# BCM2711_PCIE register map
File version: 1
BCM2711 PCIe bridge
Registers are read-write, no defined reset value unless marked. A register's access mark holds for its fields unless they carry their own. Offsets are from the block's base; lines under a group give offsets from that group; [hi:lo] are bit positions; {n}, {i} and the like mark numbered series; 'fields as' and 'values as' point back to an identical list; <NAME> marks a mode.

## Memory map
0x00000000 BCM2711_PCIE size 0x9310

## BCM2711_PCIE
Base 0x00000000
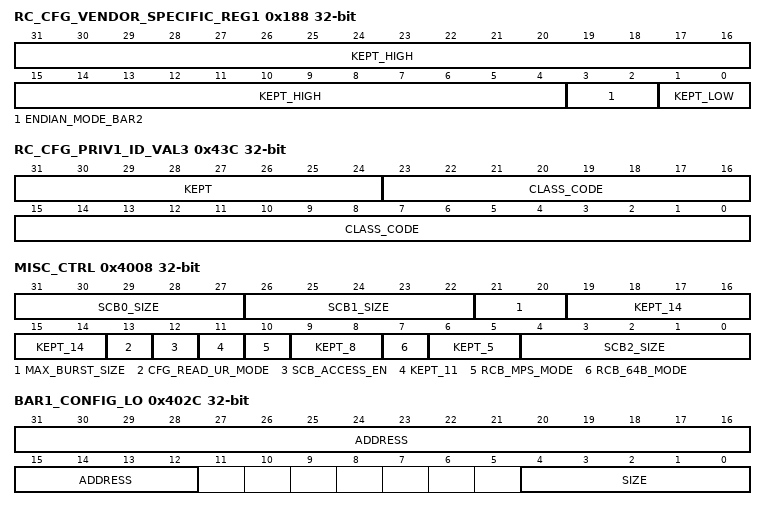
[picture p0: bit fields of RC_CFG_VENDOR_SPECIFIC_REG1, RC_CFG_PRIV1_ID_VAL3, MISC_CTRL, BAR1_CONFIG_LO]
0x188 RC_CFG_VENDOR_SPECIFIC_REG1 — The root port's vendor register 1: the inbound window's byte order
  [31:4] KEPT_HIGH — Bits no source names, kept as read
  [3:2] ENDIAN_MODE_BAR2 — Byte order of inbound window BAR2
    0=LITTLE
  [1:0] KEPT_LOW — Bits no source names, kept as read
0x43C RC_CFG_PRIV1_ID_VAL3 — The root port's class code, which resets as an endpoint's
  [31:24] KEPT — Bits no source names, kept as read
  [23:0] CLASS_CODE — Base class, subclass and programming interface
    0x60400=PCI_TO_PCI_BRIDGE
0x4008 MISC_CTRL — MISC_MISC_CTRL: bus access, burst and the memory controllers' sizes
  [31:27] SCB0_SIZE — Memory controller 0's size, as its base-2 logarithm less 15
  [26:22] SCB1_SIZE — Memory controller 1's size; unused on the BCM2711
  [21:20] MAX_BURST_SIZE — The longest burst on the system bus
    0=BYTES_128; 1=BYTES_256; 2=BYTES_512
  [19:14] KEPT_14 — Bits no source names, kept as read
  [13] CFG_READ_UR_MODE — A configuration read completing with Unsupported Request returns data (inference)
  [12] SCB_ACCESS_EN — Lets the bridge reach the system bus
  [11] KEPT_11 — A bit no source names, kept as read
  [10] RCB_MPS_MODE — Read completion boundary from the payload size; no source says what it changes
  [9:8] KEPT_8 — Bits no source names, kept as read
  [7] RCB_64B_MODE — Read completion boundary of 64 bytes; no source says what it changes
  [6:5] KEPT_5 — Bits no source names, kept as read
  [4:0] SCB2_SIZE — Memory controller 2's size; unused on the BCM2711
{0x400C+8i} WIN_LO[{i}] (i=0..3) — CPU_2_PCIE_MEM_WIN_LO: outbound window w's PCI address, low word
  [31:0] ADDRESS — The PCI address's bits 31:0
{0x4010+8i} WIN_HI[{i}] (i=0..3) — CPU_2_PCIE_MEM_WIN_HI: outbound window w's PCI address, high word
  [31:0] ADDRESS — The PCI address's bits 63:32
0x402C BAR1_CONFIG_LO — MISC_RC_BAR1_CONFIG_LO: inbound window 1, which on this family maps the SoC's registers; kept disabled
  [31:12] ADDRESS — The PCI address's bits 31:12
  [4:0] SIZE — The window's size code; 0 disables it
    0=DISABLED
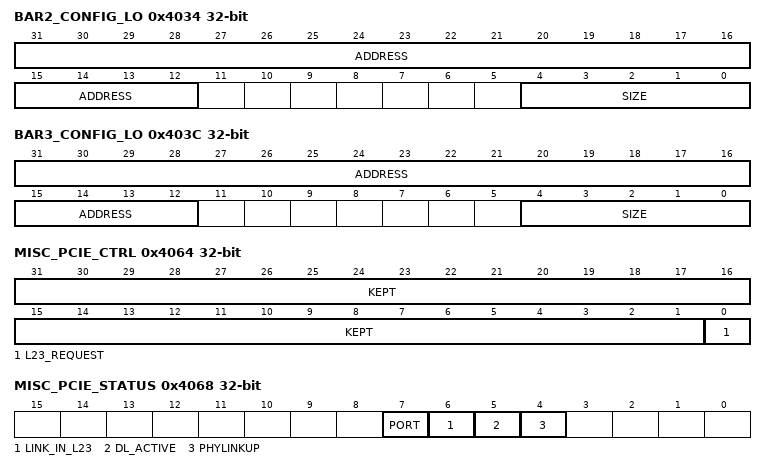
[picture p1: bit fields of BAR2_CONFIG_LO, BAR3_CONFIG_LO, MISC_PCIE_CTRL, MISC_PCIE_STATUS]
0x4034 BAR2_CONFIG_LO — MISC_RC_BAR2_CONFIG_LO: inbound window 2, the one that maps memory from CPU address 0
  [31:12] ADDRESS — The PCI address's bits 31:12
  [4:0] SIZE — The window's size code: log2(size) - 15 from 64 KiB to 64 GiB, log2(size) - 12 + 0x1c from 4 KiB to 32 KiB; 0 disables it
    0=DISABLED
0x4038 BAR2_CONFIG_HI — MISC_RC_BAR2_CONFIG_HI: inbound window 2's PCI address, high word
  [31:0] ADDRESS — The PCI address's bits 63:32
0x403C BAR3_CONFIG_LO — MISC_RC_BAR3_CONFIG_LO: inbound window 3; kept disabled
  fields as BAR1_CONFIG_LO
0x4064 MISC_PCIE_CTRL — MISC_PCIE_CTRL: the link's power-state request
  [31:1] KEPT — Bits that are not the BCM2711's or that no source names, kept as read
  [0] L23_REQUEST — Asks the link to enter L2/L3 ready
0x4068 MISC_PCIE_STATUS ro — MISC_PCIE_STATUS: the link's state and the block's mode
  [7] PORT — Whether the block is a root complex or an endpoint
    0=ENDPOINT; 1=ROOT_COMPLEX
  [6] LINK_IN_L23 — The link is in L2/L3 ready
  [5] DL_ACTIVE — The data link layer is active
  [4] PHYLINKUP — The physical link is up
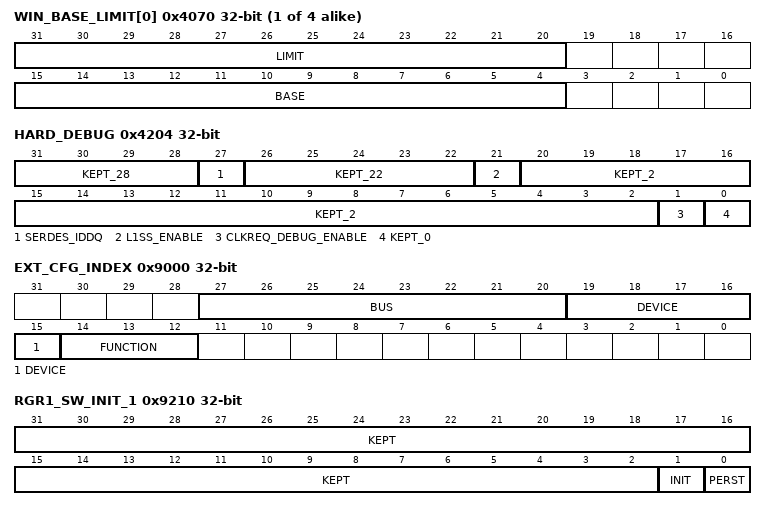
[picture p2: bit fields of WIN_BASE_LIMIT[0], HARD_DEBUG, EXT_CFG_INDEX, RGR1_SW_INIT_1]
{0x4070+4i} WIN_BASE_LIMIT[{i}] (i=0..3) — CPU_2_PCIE_MEM_WIN_BASE_LIMIT: outbound window w's CPU base and limit, low bits
  [31:20] LIMIT — The CPU limit (the last byte) in MiB, its low 12 bits
  [15:4] BASE — The CPU base in MiB, its low 12 bits
{0x4080+8i} WIN_BASE_HI[{i}] (i=0..3) — CPU_2_PCIE_MEM_WIN_BASE_HI: outbound window w's CPU base, high bits
  [7:0] BASE — The CPU base in MiB, shifted right by 12
{0x4084+8i} WIN_LIMIT_HI[{i}] (i=0..3) — CPU_2_PCIE_MEM_WIN_LIMIT_HI: outbound window w's CPU limit, high bits
  [7:0] LIMIT — The CPU limit in MiB, shifted right by 12
0x4204 HARD_DEBUG — MISC_HARD_PCIE_HARD_DEBUG: the SerDes power and clock power management
  [31:28] KEPT_28 — Bits no source names, kept as read
  [27] SERDES_IDDQ — Powers the SerDes down
  [26:22] KEPT_22 — Bits no source names, kept as read
  [21] L1SS_ENABLE — L1 substates
  [20:2] KEPT_2 — Bits the BCM2711 driver does not use or no source names, kept as read
  [1] CLKREQ_DEBUG_ENABLE — CLKREQ# clock power management
  [0] KEPT_0 — A bit no source names, kept as read
0x9000 EXT_CFG_INDEX wo — EXT_CFG_INDEX: which function EXT_CFG_DATA shows
  [27:20] BUS — The bus
  [19:15] DEVICE — The device
  [14:12] FUNCTION — The function
0x9210 RGR1_SW_INIT_1 — RGR1_SW_INIT_1: PERST# and the bridge's reset
  [31:2] KEPT — Bits no source names, kept as read
  [1] INIT — 1 holds the bridge in reset
  [0] PERST — 1 holds PERST# asserted

## Notices in the file
Copyright (c) 2026, Stanislav Sedov <stas@deglitch.com>
SPDX-License-Identifier: BSD-2-Clause
no GPL source was read for this file.
